# bao1x register map
Vendor: baochip; File version: 1.0
Registers are 32-bit, read-write, reset 0x0 unless marked. A register's access mark holds for its fields unless they carry their own. Offsets are from the block's base; [hi:lo] are bit positions; {n}, {i} and the like mark numbered series; <NAME> marks a mode.

## AOBUREG
Base 0x40065000
{0x0+4i} SFR_BUREG_CR_BUREGS{i} (i=0..7) — See `aobureg.sv#L33 <https://github.com/baochip/baochip-1x/blob/main/rtl/modules /ao/rtl/aobureg.sv#L33>`__ (line numbers are approximate)
  [31:0] cr_buregs{i} — cr_buregs read/write control register

## DKPC
Base 0x40064000
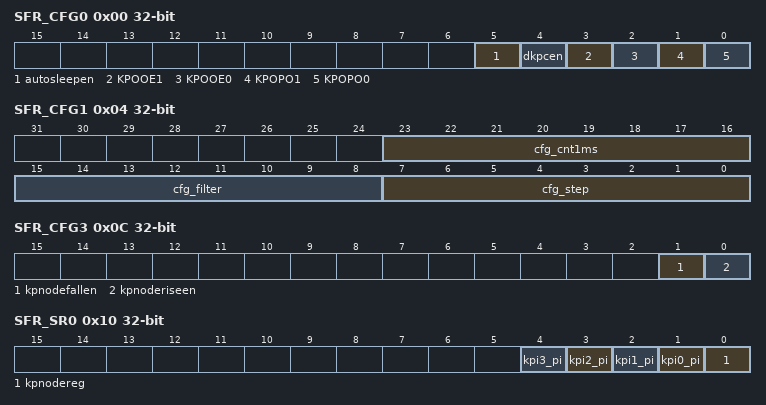
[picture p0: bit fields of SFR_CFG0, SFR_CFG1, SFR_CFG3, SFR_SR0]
0x00 SFR_CFG0 — See `dkpc.sv#L167 <https://github.com/baochip/baochip-1x/blob/main/rtl/modules/a o/rtl/dkpc.sv#L167>`__ (line numbers are approximate)
  [5] autosleepen — autosleepen read/write control register
  [4] dkpcen — dkpcen read/write control register
  [3] KPOOE1 — KPOOE1 read/write control register
  [2] KPOOE0 — KPOOE0 read/write control register
  [1] KPOPO1 — KPOPO1 read/write control register
  [0] KPOPO0 — KPOPO0 read/write control register
0x04 SFR_CFG1 — See `dkpc.sv#L168 <https://github.com/baochip/baochip-1x/blob/main/rtl/modules/a o/rtl/dkpc.sv#L168>`__ (line numbers are approximate)
  [23:16] cfg_cnt1ms — cfg_cnt1ms read/write control register
  [15:8] cfg_filter — cfg_filter read/write control register
  [7:0] cfg_step — cfg_step read/write control register
0x08 SFR_CFG2 — See `dkpc.sv#L169 <https://github.com/baochip/baochip-1x/blob/main/rtl/modules/a o/rtl/dkpc.sv#L169>`__ (line numbers are approximate)
  [31:0] cfg_cnt — cfg_cnt read/write control register
0x0C SFR_CFG3 — See `dkpc.sv#L170 <https://github.com/baochip/baochip-1x/blob/main/rtl/modules/a o/rtl/dkpc.sv#L170>`__ (line numbers are approximate)
  [1] kpnodefallen — kpnodefallen read/write control register
  [0] kpnoderiseen — kpnoderiseen read/write control register
0x10 SFR_SR0 — See `dkpc.sv#L173 <https://github.com/baochip/baochip-1x/blob/main/rtl/modules/a o/rtl/dkpc.sv#L173>`__ (line numbers are approximate)
  [n+1] kpi{n}_pi (n=0..3) — kpi[{n}].pi read only status register
  [0] kpnodereg — kpnodereg read only status register
0x14 SFR_SR1 — See `dkpc.sv#L174 <https://github.com/baochip/baochip-1x/blob/main/rtl/modules/a o/rtl/dkpc.sv#L174>`__ (line numbers are approximate)
  [0] sfr_sr1 — sfr_sr1 read only status register
0x30 SFR_CFG4 — See `dkpc.sv#L171 <https://github.com/baochip/baochip-1x/blob/main/rtl/modules/a o/rtl/dkpc.sv#L171>`__ (line numbers are approximate)
  [15:0] sfr_cfg4 — sfr_cfg4 read/write control register

## UDMA_CTRL
Base 0x50100000
0x00 REG_CG — See `udma_ctrl.sv <https://github.com/baochip/baochip-1x/blob/main/rtl/ips/udma/ udma_core/rtl/common/udma_ctrl.sv>`__
  [5:0] r_cg
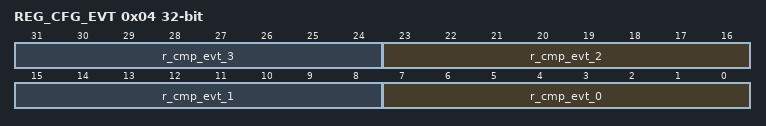
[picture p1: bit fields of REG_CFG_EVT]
0x04 REG_CFG_EVT — See `udma_ctrl.sv <https://github.com/baochip/baochip-1x/blob/main/rtl/ips/udma/ udma_core/rtl/common/udma_ctrl.sv>`__
  [8n+7:8n] r_cmp_evt_{n} (n=0..3)
0x08 REG_RST — See `udma_ctrl.sv <https://github.com/baochip/baochip-1x/blob/main/rtl/ips/udma/ udma_core/rtl/common/udma_ctrl.sv>`__
  [5:0] r_rst

## UDMA_UART_0
Base 0x50101000
Same registers: UDMA_UART_1 0x50102000, UDMA_UART_2 0x50103000, UDMA_UART_3 0x50104000
0x00 REG_RX_SADDR — See `udma_uart_reg_if.sv <https://github.com/baochip/baochip-1x/blob/main/rtl/ip s/udma/udma_uart/rtl/udma_uart_reg_if.sv>`__
  [11:0] r_rx_startaddr
0x04 REG_RX_SIZE — See `udma_uart_reg_if.sv <https://github.com/baochip/baochip-1x/blob/main/rtl/ip s/udma/udma_uart/rtl/udma_uart_reg_if.sv>`__
  [15:0] r_rx_size
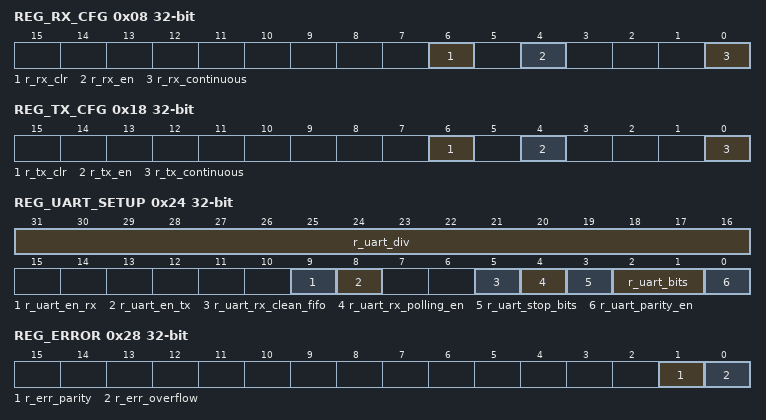
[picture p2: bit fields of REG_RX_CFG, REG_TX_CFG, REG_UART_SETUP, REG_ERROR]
0x08 REG_RX_CFG — See `udma_uart_reg_if.sv <https://github.com/baochip/baochip-1x/blob/main/rtl/ip s/udma/udma_uart/rtl/udma_uart_reg_if.sv>`__
  [6] r_rx_clr, [4] r_rx_en, [0] r_rx_continuous
0x10 REG_TX_SADDR — See `udma_uart_reg_if.sv <https://github.com/baochip/baochip-1x/blob/main/rtl/ip s/udma/udma_uart/rtl/udma_uart_reg_if.sv>`__
  [11:0] r_tx_startaddr
0x14 REG_TX_SIZE — See `udma_uart_reg_if.sv <https://github.com/baochip/baochip-1x/blob/main/rtl/ip s/udma/udma_uart/rtl/udma_uart_reg_if.sv>`__
  [15:0] r_tx_size
0x18 REG_TX_CFG — See `udma_uart_reg_if.sv <https://github.com/baochip/baochip-1x/blob/main/rtl/ip s/udma/udma_uart/rtl/udma_uart_reg_if.sv>`__
  [6] r_tx_clr, [4] r_tx_en, [0] r_tx_continuous
0x20 REG_STATUS — See `udma_uart_reg_if.sv <https://github.com/baochip/baochip-1x/blob/main/rtl/ip s/udma/udma_uart/rtl/udma_uart_reg_if.sv>`__
  [0] status_i
0x24 REG_UART_SETUP — See `udma_uart_reg_if.sv <https://github.com/baochip/baochip-1x/blob/main/rtl/ip s/udma/udma_uart/rtl/udma_uart_reg_if.sv>`__
  [31:16] r_uart_div, [9] r_uart_en_rx, [8] r_uart_en_tx, [5] r_uart_rx_clean_fifo, [4] r_uart_rx_polling_en, [3] r_uart_stop_bits, [2:1] r_uart_bits, [0] r_uart_parity_en
0x28 REG_ERROR — See `udma_uart_reg_if.sv <https://github.com/baochip/baochip-1x/blob/main/rtl/ip s/udma/udma_uart/rtl/udma_uart_reg_if.sv>`__
  [1] r_err_parity, [0] r_err_overflow
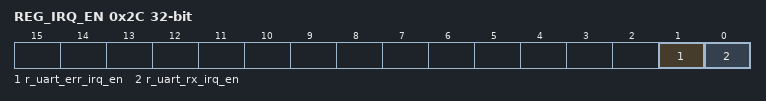
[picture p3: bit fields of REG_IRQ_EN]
0x2C REG_IRQ_EN — See `udma_uart_reg_if.sv <https://github.com/baochip/baochip-1x/blob/main/rtl/ip s/udma/udma_uart/rtl/udma_uart_reg_if.sv>`__
  [1] r_uart_err_irq_en, [0] r_uart_rx_irq_en
0x30 REG_VALID — See `udma_uart_reg_if.sv <https://github.com/baochip/baochip-1x/blob/main/rtl/ip s/udma/udma_uart/rtl/udma_uart_reg_if.sv>`__
  [0] r_uart_rx_data_valid
0x34 REG_DATA — See `udma_uart_reg_if.sv <https://github.com/baochip/baochip-1x/blob/main/rtl/ip s/udma/udma_uart/rtl/udma_uart_reg_if.sv>`__
  [7:0] r_uart_rx_data
